BO_ 148 Vehicle_Speed: 8 XXX
 SG_ Vehicle_Speed : 5|12@0- (0.05,0) [0|254] "" XXX

BO_ 175 Accelerator_True_Pedal_Pos_and_Brake_State: 8 XXX
 SG_ Accelerator_True_Pedal_Position : 7|8@0+ (0.392157,0) [0|100] "%" XXX
 SG_ Brake_True_Pedal_State : 31|1@0+ (1,0) [0|1] "" XXX

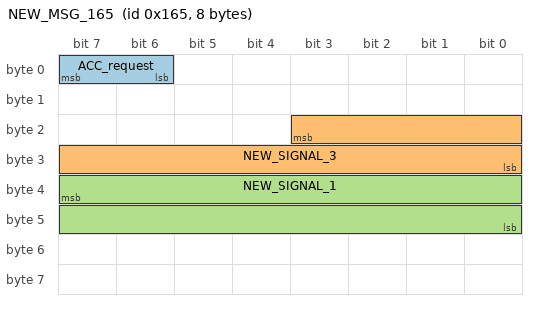
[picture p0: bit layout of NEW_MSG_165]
BO_ 357 NEW_MSG_165: 8 XXX
 SG_ ACC_request : 7|2@0+ (1,0) [0|3] "" XXX
 SG_ NEW_SIGNAL_3 : 19|12@0+ (1,0) [0|4095] "" XXX
 SG_ NEW_SIGNAL_1 : 39|16@0+ (1,0) [0|65535] "" XXX

BO_ 406 Accelerator_Effective_Position: 8 XXX
 SG_ Accelerator_Effective_Pedal_Position : 47|8@0+ (1,0) [0|255] "" XXX

BO_ 412 Motor: 8 XXX
 SG_ Drive_shaft_torque : 19|12@0+ (0.5,-848) [0|4095] "Nm" XXX
 SG_ Drive_shaft_rpm : 39|16@0+ (1,-32767) [-32767|32768] "rpm" XXX

BO_ 438 Brake_System: 8 XXX
 SG_ Brake_Pedal_Applied : 10|1@0+ (1,0) [0|1] "" XXX

BO_ 485 Steering_Angle: 8 XXX
 SG_ Steering_Angle : 15|16@0+ (0.0625,-2048) [0|65535] "degree" XXX

BO_ 532 Brake_Pressure: 6 XXX
 SG_ Brake_Pressure : 15|8@0+ (75,0) [0|63] "kPa" XXX

BO_ 540 Dashboard: 8 XXX
 SG_ Wipers_Switch : 47|2@0+ (1,0) [0|3] "" XXX
 SG_ Dashboard_Speed : 55|8@0+ (1,0) [0|254] "km/h" XXX

BO_ 840 Wheel_Speed_Front: 8 XXX
 SG_ Front_Left : 5|14@0+ (0.03125,0) [0|65535] "kph" XXX
 SG_ Front_Right : 21|14@0+ (0.03125,0) [0|65535] "kph" XXX

BO_ 842 Wheel_Speed_Rear: 8 XXX
 SG_ Rear_Left : 5|14@0+ (0.03125,0) [0|65535] "kph" XXX
 SG_ Rear_Right : 21|14@0+ (0.03125,0) [0|65535] "kph" XXX

CM_ SG_ 532 Brake_Pressure "Brake Pressure";
VAL_ 175 Brake_True_Pedal_State 0 "Not Applied" 1 "Applied";
VAL_ 438 Brake_Pedal_Applied 0 "Not Applied" 1 "Applied";
VAL_ 540 Wipers_Switch 0 "Wipers off" 1 "Wipers on intermittent" 2 "Wipers on slow" 3 "Wipers on fast";
VAL_ 540 Dashboard_Speed 255 "Missing";
